AUTOSAR XML (schema 00049)
standard types defined: boolean, uint8, boolean_CompuMethod, boolean_DataConstr
package /ComponentTypes
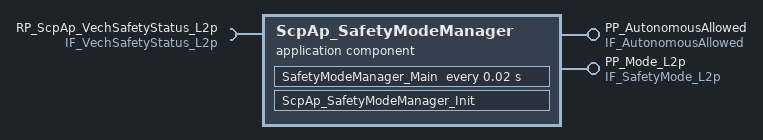
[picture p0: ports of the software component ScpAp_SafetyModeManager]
  application sw component type ScpAp_SafetyModeManager
    require port RP_ScpAp_VechSafetyStatus_L2p: nonqueued-receiver-com-spec{data-element=IF_VechSafetyStatus_L2p, init-value=NORMAL}, required-interface=IF_VechSafetyStatus_L2p
    provide port PP_AutonomousAllowed: nonqueued-sender-com-spec{data-element=IF_AutonomousAllowed, init-value=AUTONOMOUS}, provided-interface=IF_AutonomousAllowed
    provide port PP_Mode_L2p: nonqueued-sender-com-spec{data-element=IF_SafetyMode_L2p, init-value=ComSpec0b429acc_2438eb9e00c18629:AUTONOMOUS}, provided-interface=IF_SafetyMode_L2p
    behavior ScpAp_SafetyModeManager_InternalBehavior: handle-termination-and-restart=NO-SUPPORT
      static-memorys:
        4 x data, all with category=VALUE, sw-addr-method=AswVariable, sw-calibration-access=READ-ONLY:
          ScpAp_SafetyModeMana_Status_Chk: type=boolean
          ScpAp_SafetyModeManage_Mode_Chk: type=boolean
          ScpAp_SafetyM_AutonomousAllowed: type=SafetyMode_L2p_IDT
          ScpAp_SafetyModeManage_Mode_L2p: type=SafetyMode_L2p_IDT
      timing event TMT_SafetyModeManager_Main: start-on-event=SafetyModeManager_Main, period=0.02
      runnable SafetyModeManager_Main: sw-addr-method=CODE
        data-receive-point-by-arguments:
          access IN_RP_ScpAp_VechSafetyStatus_L2p_IF_VechSafetyStatus_L2p: accessed-variable=RP_ScpAp_VechSafetyStatus_L2p.IF_VechSafetyStatus_L2p
        data-send-points:
          access OUT_PP_AutonomousAllowed_IF_AutonomousAllowed: accessed-variable=PP_AutonomousAllowed.IF_AutonomousAllowed
          access OUT_PP_Mode_L2p_IF_SafetyMode_L2p: accessed-variable=PP_Mode_L2p.IF_SafetyMode_L2p
      runnable ScpAp_SafetyModeManager_Init: sw-addr-method=CODE
package /DataTypes
  impl type SafetyMode_L2p_IDT: category=VALUE, base-type=BaseTypes/uint8, compu {1=AUTONOMOUS, 0=MANUAL, 3=TELEOPS}, data-constr=DC_SafetyMode_L2p_IDT
  impl type VechSafetyStatus_L2p_IDT: category=VALUE, base-type=BaseTypes/uint8, compu {0=NORMAL, 1=DEGRADED, 3=FAULT_STOP}, data-constr=DC_VechSafetyStatus_L2p_IDT
package /PortInterfaces
  sender receiver interface IF_AutonomousAllowed: invalidation-policy{data-element=IF_AutonomousAllowed, handle-invalid=DONT-INVALIDATE}
    data IF_AutonomousAllowed: category=VALUE, sw-calibration-access=READ-ONLY, type=SafetyMode_L2p_IDT
  sender receiver interface IF_SafetyMode_L2p: invalidation-policy{data-element=IF_SafetyMode_L2p, handle-invalid=DONT-INVALIDATE}
    data IF_SafetyMode_L2p: category=VALUE, sw-calibration-access=READ-ONLY, type=SafetyMode_L2p_IDT
  sender receiver interface IF_VechSafetyStatus_L2p: invalidation-policy{data-element=IF_VechSafetyStatus_L2p, handle-invalid=DONT-INVALIDATE}
    data IF_VechSafetyStatus_L2p: category=VALUE, sw-calibration-access=READ-ONLY, type=VechSafetyStatus_L2p_IDT
